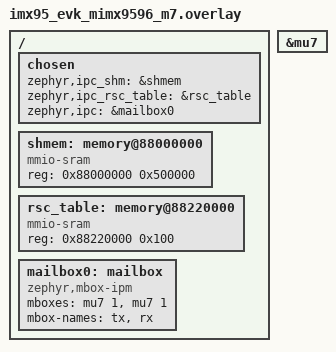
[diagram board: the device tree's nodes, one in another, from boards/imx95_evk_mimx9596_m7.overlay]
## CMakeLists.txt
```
# Copyright (c) 2026 Golioth, Inc.
#
# SPDX-License-Identifier: Apache-2.0

cmake_minimum_required(VERSION 3.20.0)

find_package(Zephyr REQUIRED HINTS $ENV{ZEPHYR_BASE})
project(rpmsg_device)

target_sources(app PRIVATE
  src/main.c
  src/credentials.c
)

if(CONFIG_EXAMPLE_FW_RELAY OR CONFIG_EXAMPLE_FW_SIGNED_URL)
  target_sources(app PRIVATE src/fw_update.c)
endif()

target_sources_ifdef(CONFIG_EXAMPLE_FW_RELAY app PRIVATE src/fw_relay.c)
target_sources_ifdef(CONFIG_EXAMPLE_FW_SIGNED_URL app PRIVATE src/fw_signed_url.c)

# Signing needs a wall clock, so signy selects POSIX_TIMERS, which in Zephyr
# 4.4 requires POSIX_SYSTEM_INTERFACES, which puts include/zephyr/posix on the
# global include path. mbedTLS then finds <arpa/inet.h> through __has_include()
# while looking for inet_pton(), and that header declares its functions with
# sa_family_t - a type only defined when the networking stack is built. A device
# that speaks Pouch over rpmsg has no IP stack, so x509_crt.c fails to compile.
#
# Aliasing the type to the one the networking headers actually define is enough:
# arpa/inet.h pulls in zephyr/net/net_ip.h, where net_sa_family_t is defined
# unconditionally. Nothing here calls inet_pton(); the declaration only has to
# parse. Drop this once Zephyr's arpa/inet.h stops depending on a type it does
# not define, or once signy stops requiring Zephyr's POSIX clock - reported as
# https://github.com/golioth/signy/issues/18.
#
# Keyed on the headers being present rather than on this sample using signy:
# enabling CONFIG_SIGNY is what puts them there, and that can outlive any one
# of the options above - a build with the transport support compiled but the
# sample's signed-URL path switched off still needs this.
if(CONFIG_POSIX_SYSTEM_INTERFACES AND NOT CONFIG_NETWORKING)
  zephyr_compile_definitions(sa_family_t=net_sa_family_t)
endif()
```

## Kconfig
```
# Copyright (c) 2026 Golioth, Inc.
#
# SPDX-License-Identifier: Apache-2.0

mainmenu "Pouch rpmsg device example"

config EXAMPLE_FW_RELAY
    bool "Relay the firmware image through this core"
    depends on POUCH_SERIAL_FW_RELAY
    default y
    help
      Download this core's image through Pouch OTA and stream the plaintext to
      the host over the firmware channel. Works against any host that collects
      that channel, and is the fallback when a URL cannot be signed.

config EXAMPLE_FW_SIGNED_URL
    bool "Hand the host a signed URL for the firmware image"
    depends on POUCH_SERIAL_FW_SIGNED_URL
    depends on SIGNY
    default y
    help
      Sign a URL for this core's own artifact and let the host fetch the image
      itself, so no image byte crosses the link. Preferred over the relay where
      both are available.

      Requires signed URLs to be enabled for the Golioth project and the CA
      that issued the device certificate to be uploaded to it. A device whose
      certificate the cloud will not accept falls back to the relay.

config EXAMPLE_SIGNED_URL_BASE
    string "Base URL for OTA artifacts"
    depends on EXAMPLE_FW_SIGNED_URL
    default "https://gw.golioth.io/.u/c/"
    help
      The artifact URL is this base followed by "package@version". The manifest
      does carry a URI field, but the SDK does not decode it today, so the URL
      is composed here instead.

config EXAMPLE_FW_COMPONENT
    string "OTA component to use for firmware update"
    depends on EXAMPLE_FW_RELAY || EXAMPLE_FW_SIGNED_URL
    default "rpmsg_device"
    help
      Name of the component in the OTA manifest carrying this core's firmware.
      The host verifies and applies it through remoteproc - this core has no
      flash of its own.

source "Kconfig.zephyr"
```

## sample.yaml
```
sample:
  description: Pouch device over the serial transport's rpmsg and UART adapters (SAEAD)
  name: rpmsg_device
tests:
  sample.pouch.rpmsg_device:
    build_only: true
    platform_allow:
      - native_sim
      - native_sim/native/64
    integration_platforms:
      - native_sim
    tags:
      - pouch
```

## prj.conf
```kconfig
# Copyright (c) 2026 Golioth, Inc.
#
# SPDX-License-Identifier: Apache-2.0

CONFIG_MAIN_STACK_SIZE=4096
CONFIG_SYSTEM_WORKQUEUE_STACK_SIZE=2048

CONFIG_LOG=y

# uart0 stays the console; uart1 carries the Pouch serial link on its own pty.
CONFIG_SERIAL=y
CONFIG_UART_INTERRUPT_DRIVEN=y

CONFIG_POUCH=y
CONFIG_POUCH_TRANSPORT_SERIAL=y
CONFIG_POUCH_SERIAL_UART_DEVICE=y

# Pouch uses SAEAD end-to-end encryption by default, which pulls in the PSA/
# mbedTLS crypto it needs. Provide the mbedTLS heap and disable the p256m
# driver (as the other examples do) so the SAEAD curves build.
CONFIG_MBEDTLS=y
CONFIG_MBEDTLS_BUILTIN=y
CONFIG_MBEDTLS_ENABLE_HEAP=y
CONFIG_MBEDTLS_HEAP_SIZE=32768
CONFIG_MBEDTLS_PSA_P256M_DRIVER_ENABLED=n
CONFIG_MBEDTLS_PKCS5_C=n
CONFIG_TEST_RANDOM_GENERATOR=y
```

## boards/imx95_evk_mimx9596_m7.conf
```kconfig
# Copyright (c) 2026 Golioth, Inc.
#
# SPDX-License-Identifier: Apache-2.0
#
# i.MX95 M7: Pouch over rpmsg against a Linux virtio-rpmsg host
# (remoteproc + resource table). Platform config mirrors the
# openamp_rsc_table sample's imx95_evk fragment.

CONFIG_CLOCK_CONTROL=y
CONFIG_ARM_SCMI=y
CONFIG_IPM=y
CONFIG_IPM_MBOX=y
CONFIG_MBOX_NXP_IMX_MU=y
CONFIG_MBOX_INIT_PRIORITY=0

# System heap must cover libmetal/open-amp virtqueue state, the
# malloc(CONFIG_POUCH_SERVER_CERT_MAX_LEN) the server-cert endpoint does when
# the broker pushes the Golioth server certificate (4096 by default), AND the
# encrypted downlink blocks in flight - pouch_downlink_push() heap-allocates
# one per block and hands it to the decrypt work queue, so a fast link keeps
# many alive at once. Sizing the heap at exactly the cert length makes the
# cert allocation fail, which aborts the session right after the info
# exchange; sizing it for a slow link makes the block allocation fail mid
# firmware download, which puts the downlink channel into a permanent error
# state (the broker then sees "peer rejected transfer" on every retry).
CONFIG_HEAP_MEM_POOL_SIZE=16384

# The rpmsg management thread must run BELOW the Pouch work queue
# (CONFIG_POUCH_THREAD_PRIORITY, default 5). At equal priority the management
# thread drains the whole receive vring without ever yielding - a fast host
# pushed 137 KB in 6 ms - while the decrypt work queue never runs, so
# pouch_downlink_push() keeps heap-allocating encrypted blocks until malloc
# fails and the downlink channel errors out permanently.
CONFIG_POUCH_RPMSG_RSC_DEVICE_THREAD_PRIORITY=6

# The rpmsg rx path runs the whole serial-core receive chain (including the
# server-cert endpoint's 4 KB malloc and certificate handling) in the adapter's
# management thread. 2 KB overflows it and faults with "Illegal load of
# EXC_RETURN into PC" partway through the server-cert transfer.
CONFIG_POUCH_RPMSG_RSC_DEVICE_STACK_SIZE=8192

# The default of 2 blocks lets the uplink handlers hold every block while the
# transport is still waiting for the first encrypted one, which stalls the
# uplink for the whole session.
CONFIG_POUCH_BLOCK_COUNT=8

CONFIG_OPENAMP=y
CONFIG_OPENAMP_MASTER=n
CONFIG_OPENAMP_RSC_TABLE=y
CONFIG_OPENAMP_RSC_TABLE_NUM_RPMSG_BUFF=8
CONFIG_OPENAMP_COPY_RSC_TABLE=y
CONFIG_OPENAMP_WITH_DCACHE=y

# Use the resource-table rpmsg adapter instead of the UART one.
CONFIG_POUCH_SERIAL_UART_DEVICE=n
CONFIG_POUCH_RPMSG_RSC_DEVICE=y

# MCU-mediated OTA: this core has no flash, so it relays its own image to the
# host, which verifies and applies it through remoteproc. malloc() draws from
# whatever RAM is left after static allocations, and the downlink
# heap-allocates one buffer per encrypted block in flight, so a bigger relay
# buffer shrinks the pool the downlink needs. 32 KB leaves a comfortable arena.
CONFIG_POUCH_SERIAL_FW_RELAY=y
CONFIG_POUCH_SERIAL_FW_BUF_SIZE=32768
CONFIG_GOLIOTH=y
CONFIG_GOLIOTH_OTA=y

# Preferred over the relay: this core signs a URL for its own artifact and the
# host fetches the image, so no image byte crosses the link and none of it is
# buffered here. The relay above stays enabled as the fallback for a host that
# does not collect the URL channel, or a project without signed URLs.
CONFIG_POUCH_SERIAL_FW_SIGNED_URL=y
CONFIG_SIGNY=y

# A real Golioth device certificate is around 385 bytes of DER, which base64
# encodes to 514 characters plus a terminator - over signy's 512-byte default,
# which makes signy_init() fail with -EINVAL before a single URL is signed.
CONFIG_SIGNY_MAX_CERT_SIZE=1024

# Keep the M7 console (LPUART3) for logs.
CONFIG_CONSOLE=y
CONFIG_UART_CONSOLE=y
CONFIG_LOG=y
CONFIG_EARLY_CONSOLE=y
CONFIG_PRINTK=y
```

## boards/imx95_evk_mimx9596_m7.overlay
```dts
/*
 * Copyright (c) 2026 Golioth, Inc.
 *
 * SPDX-License-Identifier: Apache-2.0
 *
 * OpenAMP resource-table plumbing for the i.MX95 M7 talking to a Linux
 * virtio-rpmsg host. Addresses match the vdev/vring/rsc-table reserved-memory
 * nodes in NXP's Linux device tree (imx95-19x19-evk / imx95-15x15-frdm).
 */

/ {
	chosen {
		zephyr,ipc_shm = &shmem;
		zephyr,ipc_rsc_table = &rsc_table;
		zephyr,ipc = &mailbox0;
	};

	shmem: memory@88000000 {
		compatible = "mmio-sram";
		reg = <0x88000000 0x500000>;
	};

	rsc_table: memory@88220000 {
		compatible = "mmio-sram";
		reg = <0x88220000 0x100>;
	};

	mailbox0: mailbox {
		compatible = "zephyr,mbox-ipm";
		mboxes = <&mu7 1>, <&mu7 1>;
		mbox-names = "tx", "rx";
		status = "okay";
	};
};

&mu7 {
	status = "okay";
};
```

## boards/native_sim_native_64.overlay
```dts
/*
 * Copyright (c) 2026 Golioth, Inc.
 *
 * SPDX-License-Identifier: Apache-2.0
 *
 * uart0 stays the console; uart1 carries the Pouch serial link on its own pty,
 * which the broker process attaches to.
 */

/ {
	chosen {
		golioth,pouch-serial-uart = &uart1;
	};
};

&uart1 {
	status = "okay";
};
```

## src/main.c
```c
/*
 * Copyright (c) 2026 Golioth, Inc.
 *
 * SPDX-License-Identifier: Apache-2.0
 *
 * Pouch device example that syncs over the serial transport's UART device
 * adapter. On native_sim the link is a host pty (native-tty UART) that a broker
 * process attaches to; on a real MPU+MCU part the same device code runs over
 * the rpmsg adapter instead. The transport adapter initializes itself at boot,
 * so the application only initializes Pouch (with its device credentials for
 * end-to-end encryption) and registers its handlers.
 */

#include <zephyr/logging/log.h>
LOG_MODULE_REGISTER(rpmsg_device, LOG_LEVEL_INF);

#include <zephyr/kernel.h>

#include <errno.h>

#include <pouch/pouch.h>
#include <pouch/uplink.h>

#include "credentials.h"

/* Called by Pouch each time a sync collects uplink data. */
static void report_telemetry(void)
{
    static uint32_t counter;
    char payload[64];

    int len = snprintk(payload,
                       sizeof(payload),
                       "{\"uptime\":%lld,\"counter\":%u}",
                       k_uptime_get() / MSEC_PER_SEC,
                       counter++);

    pouch_uplink_entry_write(".s/telemetry", POUCH_CONTENT_TYPE_JSON, payload, len, POUCH_FOREVER);
}
POUCH_UPLINK_HANDLER(report_telemetry);

int main(void)
{
    struct pouch_config config = {0};

    int err = load_certificate(&config.certificate);
    if (err)
    {
        LOG_ERR("Failed to load certificate (err %d)", err);
        return err;
    }

    config.private_key = load_private_key();
    if (config.private_key == PSA_KEY_ID_NULL)
    {
        LOG_ERR("Failed to load private key");
        return -EIO;
    }

    err = pouch_init(&config);
    if (err)
    {
        LOG_ERR("Pouch init failed (err %d)", err);
        return err;
    }

    LOG_INF("Pouch serial/rpmsg device ready");

    return 0;
}
```

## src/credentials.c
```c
/*
 * Copyright (c) 2026 Golioth, Inc.
 *
 * SPDX-License-Identifier: Apache-2.0
 *
 * Embedded device credentials for the rpmsg example.
 *
 * The key and certificate below are auto-generated placeholders (a self-signed
 * P-256 key pair) so the example is self-contained and builds without a
 * provisioned filesystem. A real deployment must provision a device
 * certificate signed by a CA the cloud trusts (see the coap_client / ble_gatt
 * examples for the filesystem-based provisioning pattern).
 */

#include "credentials.h"

#include <mbedtls/pk.h>
#include <mbedtls/psa_util.h>

#include <zephyr/logging/log.h>
LOG_MODULE_REGISTER(credentials, LOG_LEVEL_INF);

static const uint8_t device_key[] = {
#include "device_key.der.inc"
};

static const uint8_t device_crt[] = {
#include "device_crt.der.inc"
};

/*
 * A PSA key carries one permitted algorithm and one usage mask, so the same key
 * material has to be imported once per purpose: deriving the Pouch session key,
 * and - where signed-URL updates are built in - signing.
 */
static psa_key_id_t import_raw_pk(const uint8_t *private_key,
                                  size_t size,
                                  psa_algorithm_t alg,
                                  psa_key_usage_t usage)
{
    mbedtls_pk_context pk;
    mbedtls_pk_init(&pk);

    int err = mbedtls_pk_parse_key(&pk, private_key, size, NULL, 0);
    if (err)
    {
        LOG_ERR("Failed to parse key: -0x%x", -err);
        mbedtls_pk_free(&pk);
        return PSA_KEY_ID_NULL;
    }

    psa_key_attributes_t attrs = PSA_KEY_ATTRIBUTES_INIT;

    psa_set_key_algorithm(&attrs, alg);
    psa_set_key_type(&attrs, PSA_KEY_TYPE_ECC_KEY_PAIR(PSA_ECC_FAMILY_SECP_R1));
    psa_set_key_usage_flags(&attrs, usage);

    psa_key_id_t key_id;
    err = mbedtls_pk_import_into_psa(&pk, &attrs, &key_id);
    mbedtls_pk_free(&pk);
    if (err)
    {
        LOG_ERR("Failed to import private key: -0x%x", -err);
        return PSA_KEY_ID_NULL;
    }

    return key_id;
}

psa_key_id_t load_private_key(void)
{
    return import_raw_pk(device_key, sizeof(device_key), PSA_ALG_ECDH, PSA_KEY_USAGE_DERIVE);
}

#if defined(CONFIG_EXAMPLE_FW_SIGNED_URL)
psa_key_id_t load_signing_key(void)
{
    return import_raw_pk(device_key,
                         sizeof(device_key),
                         PSA_ALG_ECDSA(PSA_ALG_SHA_256),
                         PSA_KEY_USAGE_SIGN_HASH);
}
#endif

int load_certificate(struct pouch_cert *cert)
{
    cert->buffer = device_crt;
    cert->size = sizeof(device_crt);
    return 0;
}
```

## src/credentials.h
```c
/*
 * Copyright (c) 2026 Golioth, Inc.
 *
 * SPDX-License-Identifier: Apache-2.0
 */
#pragma once

#include <psa/crypto.h>

#include <pouch/types.h>

/**
 * Import the embedded device private key into PSA.
 *
 * @return The assigned PSA key ID, or PSA_KEY_ID_NULL on failure.
 */
psa_key_id_t load_private_key(void);

#if defined(CONFIG_EXAMPLE_FW_SIGNED_URL)
/**
 * Import the embedded device private key again, for signing.
 *
 * A PSA key permits one algorithm, and the key that derives the Pouch session
 * key cannot also sign, so signed-URL updates need their own import of the same
 * material.
 *
 * @return The assigned PSA key ID, or PSA_KEY_ID_NULL on failure.
 */
psa_key_id_t load_signing_key(void);
#endif

/**
 * Point @p cert at the embedded device certificate.
 *
 * @return 0 on success.
 */
int load_certificate(struct pouch_cert *cert);
```

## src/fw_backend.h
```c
/*
 * Copyright (c) 2026 Golioth, Inc.
 *
 * SPDX-License-Identifier: Apache-2.0
 */
#pragma once

#include <stdbool.h>
#include <stddef.h>
#include <stdint.h>

#include <pouch/transport/serial/fw.h>

/**
 * An update the cloud has offered and this core has not finished acting on.
 *
 * The manifest's strings only live for the duration of the manifest handler,
 * but an update the host rejects has to be restarted long after that, so the
 * dispatcher keeps a copy and hands it to whichever backend is in use.
 */
struct fw_pending
{
    char version[POUCH_SERIAL_FW_MAX_NAME_LEN + 1];
    uint8_t hash[32];
    size_t size;
};

/*
 * The two ways this core can be updated. Both end in the host restarting it
 * with a new image; they differ in who moves the bytes.
 */

#if defined(CONFIG_EXAMPLE_FW_RELAY)
/** Download the image through Pouch and stream the plaintext to the host. */
int fw_relay_start(const struct fw_pending *pending);
/** Abandon a relay in progress, so a later offer can start cleanly. */
void fw_relay_abort(void);
/** Feed the relay one block of the component, from the OTA callback. */
void fw_relay_receive(const void *data, size_t offset, size_t len, bool is_last);
#endif

#if defined(CONFIG_EXAMPLE_FW_SIGNED_URL)
/** True once a URL can actually be signed: credentials loaded, clock set. */
bool fw_signed_url_ready(void);
/** Hand the host a signed URL for the artifact and let it fetch the image. */
int fw_signed_url_start(const struct fw_pending *pending);
/** Withdraw a handoff that has not been collected yet. */
void fw_signed_url_abort(void);
#endif
```

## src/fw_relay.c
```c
/*
 * Copyright (c) 2026 Golioth, Inc.
 *
 * SPDX-License-Identifier: Apache-2.0
 *
 * Relay backend: download the image through Pouch OTA and stream the plaintext
 * out to the host over the serial firmware channel. The host verifies the
 * SHA-256 from the manifest, installs the image next to the previous one, and
 * restarts this core.
 *
 * Only a block-sized buffer of RAM is used: relaying blocks while the outgoing
 * buffer is full, which throttles the download to the speed of the link.
 */

#include <zephyr/logging/log.h>
LOG_MODULE_REGISTER(fw_relay, LOG_LEVEL_INF);

#include <zephyr/kernel.h>

#include <golioth/ota.h>
#include <pouch/transport/serial/fw.h>

#include "fw_backend.h"

#define FW_COMPONENT CONFIG_EXAMPLE_FW_COMPONENT

static bool relaying;

int fw_relay_start(const struct fw_pending *pending)
{
    int err = pouch_serial_fw_begin(FW_COMPONENT,
                                    pending->version,
                                    (uint32_t) pending->size,
                                    pending->hash);
    if (err)
    {
        LOG_ERR("Failed to start firmware relay: %d", err);
        return err;
    }

    relaying = true;
    golioth_ota_mark_for_download(FW_COMPONENT);
    return 0;
}

void fw_relay_abort(void)
{
    pouch_serial_fw_abort();
    relaying = false;
}

/* Runs on the downlink decrypt work queue. Blocking here is deliberate: it is
 * the backpressure that stops the cloud outrunning the serial link.
 */
void fw_relay_receive(const void *data, size_t offset, size_t len, bool is_last)
{
    if (!relaying)
    {
        return;
    }

    /* Blocking here is the backpressure that stops the cloud outrunning the
     * link: the broker drains the firmware channel concurrently with this
     * downlink, so waiting does make progress. It is still bounded rather than
     * indefinite - a broker that never collects the firmware channel would
     * otherwise wedge the session that is supposed to drain it.
     */
    int ret = pouch_serial_fw_write(data, len, POUCH_SECONDS(5));
    if (ret < (int) len)
    {
        LOG_ERR("Firmware relay stalled at offset %zu (%d/%zu) - abandoning update",
                offset,
                ret,
                len);
        relaying = false;
        pouch_serial_fw_abort();
        golioth_ota_mark_idle(FW_COMPONENT);
        return;
    }

    if (is_last)
    {
        LOG_INF("Relayed %zu bytes, awaiting host apply", offset + len);
        pouch_serial_fw_end();
        relaying = false;

        /* The host verifies and restarts this core. Marking updating stops the
         * cloud sending more component data in the meantime.
         */
        golioth_ota_mark_updating(FW_COMPONENT);
    }
}
```

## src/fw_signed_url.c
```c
/*
 * Copyright (c) 2026 Golioth, Inc.
 *
 * SPDX-License-Identifier: Apache-2.0
 *
 * Signed-URL backend: sign a URL for this core's own artifact and hand it to
 * the host, which fetches the image itself. No image byte crosses the link and
 * nothing is buffered here.
 *
 * The signature is what makes this safe to hand over: it is made with the
 * device key, which never leaves this core, and it is valid only for one
 * artifact and only for a short window. The host gains the ability to fetch
 * that one file, and nothing else.
 */

#include <zephyr/logging/log.h>
LOG_MODULE_REGISTER(fw_signed_url, LOG_LEVEL_INF);

#include <zephyr/init.h>
#include <zephyr/kernel.h>

#include <stdio.h>
#include <time.h>

#include <golioth/ota.h>
#include <pouch/transport/serial/fw_url.h>
#include <signy/signy.h>

#include "credentials.h"
#include "fw_backend.h"

#define FW_COMPONENT CONFIG_EXAMPLE_FW_COMPONENT

/* Base plus "package@version": both names are bounded by the wire format. */
#define URL_MAX (sizeof(CONFIG_EXAMPLE_SIGNED_URL_BASE) + 2 * POUCH_SERIAL_FW_MAX_NAME_LEN + 2)

static bool signy_ready;

bool fw_signed_url_ready(void)
{
    /* A signature carries the window it is valid for, so an unset clock
     * produces one the cloud will refuse. The host reports its own time on the
     * time channel, and only a host that implements this handoff does - so this
     * is also the test for whether there is anyone to hand a URL to.
     */
    return signy_ready && pouch_serial_time_synced();
}

int fw_signed_url_start(const struct fw_pending *pending)
{
    char url[URL_MAX];

    int n = snprintk(url,
                     sizeof(url),
                     "%s%s@%s",
                     CONFIG_EXAMPLE_SIGNED_URL_BASE,
                     FW_COMPONENT,
                     pending->version);
    if (n < 0 || n >= (int) sizeof(url))
    {
        LOG_ERR("Artifact URL does not fit");
        return -ENOMEM;
    }

    int err = pouch_serial_fw_url_begin(FW_COMPONENT,
                                        pending->version,
                                        (uint32_t) pending->size,
                                        pending->hash,
                                        url);
    if (err)
    {
        LOG_ERR("Failed to announce the artifact: %d", err);
        return err;
    }

    LOG_INF("Announced %s for the host to fetch", url);

    /* The image never comes through Pouch, so the component is not marked for
     * download. It is marked updating: the cloud has to stop offering it while
     * the host works, and the result comes back as an apply verdict.
     */
    golioth_ota_mark_updating(FW_COMPONENT);
    return 0;
}

void fw_signed_url_abort(void)
{
    pouch_serial_fw_url_abort();
}

static void set_clock(int64_t unix_seconds)
{
    struct timespec ts = {
        .tv_sec = (time_t) unix_seconds,
        .tv_nsec = 0,
    };

    if (clock_settime(CLOCK_REALTIME, &ts) != 0)
    {
        LOG_ERR("Failed to set the clock from the host");
        return;
    }

    LOG_DBG("Clock set from the host: %lld", (long long) unix_seconds);
}

static int fw_signed_url_init(void)
{
    struct pouch_cert cert;

    pouch_serial_time_callback_set(set_clock);

    psa_key_id_t key = load_signing_key();
    if (key == PSA_KEY_ID_NULL)
    {
        LOG_ERR("No signing key; signed-URL updates are unavailable");
        return 0;
    }

    if (load_certificate(&cert) != 0)
    {
        LOG_ERR("No device certificate; signed-URL updates are unavailable");
        return 0;
    }

    int err = signy_init(key, cert.buffer, cert.size);
    if (err != 0)
    {
        /* -EINVAL here is most often the encoded certificate overflowing
         * CONFIG_SIGNY_MAX_CERT_SIZE, which the default does for a real
         * Golioth device certificate.
         */
        LOG_ERR("Failed to initialize signy: %d", err);
        return 0;
    }

    pouch_serial_fw_url_signer_set(signy_sign_url);
    signy_ready = true;

    LOG_INF("Signed-URL updates available once the host reports its time");
    return 0;
}

SYS_INIT(fw_signed_url_init, APPLICATION, CONFIG_APPLICATION_INIT_PRIORITY);
```

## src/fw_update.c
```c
/*
 * Copyright (c) 2026 Golioth, Inc.
 *
 * SPDX-License-Identifier: Apache-2.0
 *
 * Host-mediated firmware update.
 *
 * This core has no flash of its own - the host loads it through remoteproc at
 * every boot - so it cannot apply an update itself. It is still the
 * authenticated Pouch endpoint, so it is the one the cloud offers updates to,
 * and it arranges for the host to install one.
 *
 * There are two ways to arrange that, and this file chooses between them per
 * attempt. Handing the host a signed URL is preferred: the host fetches the
 * image directly and no byte of it crosses the link. Relaying the image through
 * this core works everywhere, and is the fallback when a URL cannot be signed
 * or when the host would not accept one.
 */

#include <zephyr/logging/log.h>
LOG_MODULE_REGISTER(fw_update, LOG_LEVEL_INF);

#include <zephyr/init.h>
#include <zephyr/kernel.h>

#include <string.h>

#include <golioth/ota.h>
#include <pouch/transport/serial/fw.h>

#include <app_version.h>

#include "fw_backend.h"

#define FW_COMPONENT CONFIG_EXAMPLE_FW_COMPONENT

/*
 * How many times to re-offer an image the host rejects before giving up. A
 * rejection is usually a corrupt transfer, which a retry fixes; a genuinely bad
 * image would otherwise retry every session forever.
 */
#define FW_MAX_ATTEMPTS 3

enum fw_mode
{
    FW_MODE_NONE,
    FW_MODE_SIGNED_URL,
    FW_MODE_RELAY,
};

static struct
{
    struct fw_pending image;
    enum fw_mode mode;
    int attempts;
    bool valid;
    /* Set when a signed-URL attempt came back rejected. The next attempt falls
     * back to the relay: the likely causes - signed URLs not enabled for the
     * project, or a certificate authority the cloud does not know - are not
     * things a second signature would fix.
     */
    bool url_rejected;
} update;

static enum fw_mode pick_mode(void)
{
#if defined(CONFIG_EXAMPLE_FW_SIGNED_URL)
    if (!update.url_rejected && fw_signed_url_ready())
    {
        return FW_MODE_SIGNED_URL;
    }
#endif

#if defined(CONFIG_EXAMPLE_FW_RELAY)
    return FW_MODE_RELAY;
#else
    return FW_MODE_NONE;
#endif
}

static int start_attempt(void)
{
    update.mode = pick_mode();

    switch (update.mode)
    {
#if defined(CONFIG_EXAMPLE_FW_SIGNED_URL)
        case FW_MODE_SIGNED_URL:
            LOG_INF("Handing the host a signed URL for %s", update.image.version);
            return fw_signed_url_start(&update.image);
#endif
#if defined(CONFIG_EXAMPLE_FW_RELAY)
        case FW_MODE_RELAY:
            LOG_INF("Relaying %s through this core", update.image.version);
            return fw_relay_start(&update.image);
#endif
        default:
            LOG_ERR("No way to deliver %s to the host", update.image.version);
            return -ENOTSUP;
    }
}

/* Stop whatever the current attempt left in flight. */
static void abort_attempt(void)
{
    switch (update.mode)
    {
#if defined(CONFIG_EXAMPLE_FW_SIGNED_URL)
        case FW_MODE_SIGNED_URL:
            fw_signed_url_abort();
            break;
#endif
#if defined(CONFIG_EXAMPLE_FW_RELAY)
        case FW_MODE_RELAY:
            fw_relay_abort();
            break;
#endif
        default:
            break;
    }

    update.mode = FW_MODE_NONE;
}

/* Runs on the downlink decrypt work queue. Only the relay ever sees data here:
 * a signed-URL handoff never marks the component for download, so the cloud
 * sends none.
 */
static void fw_receive(const void *data, size_t offset, size_t len, bool is_last)
{
#if defined(CONFIG_EXAMPLE_FW_RELAY)
    fw_relay_receive(data, offset, len, is_last);
#else
    ARG_UNUSED(data);
    ARG_UNUSED(offset);
    ARG_UNUSED(len);
    ARG_UNUSED(is_last);
#endif
}

GOLIOTH_OTA_COMPONENT(fw, FW_COMPONENT, APP_VERSION_STRING, fw_receive);

static void fw_manifest(const struct golioth_ota_manifest_component *components, size_t num)
{
    for (size_t i = 0; i < num; i++)
    {
        const struct golioth_ota_manifest_component *c = &components[i];

        if (strcmp(c->name, FW_COMPONENT) != 0)
        {
            continue;
        }

        if (strcmp(c->target, APP_VERSION_STRING) == 0)
        {
            LOG_DBG("Already running %s", c->target);
            continue;
        }

        LOG_INF("Update available: %s -> %s (%zu bytes)", c->current, c->target, c->size);

        if (strlen(c->target) > POUCH_SERIAL_FW_MAX_NAME_LEN)
        {
            LOG_ERR("Target version %s is too long to deliver", c->target);
            continue;
        }

        strcpy(update.image.version, c->target);
        memcpy(update.image.hash, c->target_hash, sizeof(update.image.hash));
        update.image.size = c->size;
        update.attempts = 1;
        update.url_rejected = false;
        update.valid = true;

        if (start_attempt() != 0)
        {
            update.valid = false;
            update.mode = FW_MODE_NONE;
        }
    }
}

GOLIOTH_OTA_MANIFEST_HANDLER(fw_manifest);

/*
 * The host's verdict on an image we handed it.
 *
 * This is the only place a rejection can be acted on. By the time it arrives
 * the device has called golioth_ota_mark_updating(), which tells the cloud to
 * stop offering the component, and the OTA manifest that would otherwise
 * re-offer it is delivered once per connection - so a device that waits for
 * another manifest after a rejection never retries. Re-arming from here is what
 * makes a retry possible at all.
 */
static void fw_apply_status(enum pouch_serial_fw_status status)
{
    if (status == POUCH_SERIAL_FW_STATUS_OK)
    {
        LOG_INF("Host installed %s; awaiting restart", update.image.version);
        update.valid = false;
        update.mode = FW_MODE_NONE;
        return;
    }

    LOG_WRN("Host rejected the image (status %d)", status);

    if (!update.valid)
    {
        return;
    }

    if (update.mode == FW_MODE_SIGNED_URL)
    {
        /* Not something a fresh signature would fix, so the retry - if there is
         * one - goes through the relay instead.
         */
        LOG_WRN("Signed-URL delivery was refused; falling back to the relay");
        update.url_rejected = true;
    }

    if (update.attempts >= FW_MAX_ATTEMPTS)
    {
        LOG_ERR("Giving up on %s after %d attempts", update.image.version, update.attempts);
        abort_attempt();
        update.valid = false;
        /* Leaving the component "updating" would stop the cloud sending any
         * component at all, not just this one.
         */
        golioth_ota_mark_idle(FW_COMPONENT);
        return;
    }

    /* Nothing is in flight after a verdict, but an attempt abandoned mid-image
     * would still be active - clear it either way so the next can start.
     */
    abort_attempt();

    update.attempts++;
    LOG_INF("Retrying %s (attempt %d/%d)", update.image.version, update.attempts, FW_MAX_ATTEMPTS);

    if (start_attempt() != 0)
    {
        update.valid = false;
        update.mode = FW_MODE_NONE;
        golioth_ota_mark_idle(FW_COMPONENT);
    }
}

static int fw_update_init(void)
{
    pouch_serial_fw_status_callback_set(fw_apply_status);
    return 0;
}

SYS_INIT(fw_update_init, APPLICATION, CONFIG_APPLICATION_INIT_PRIORITY);
```
